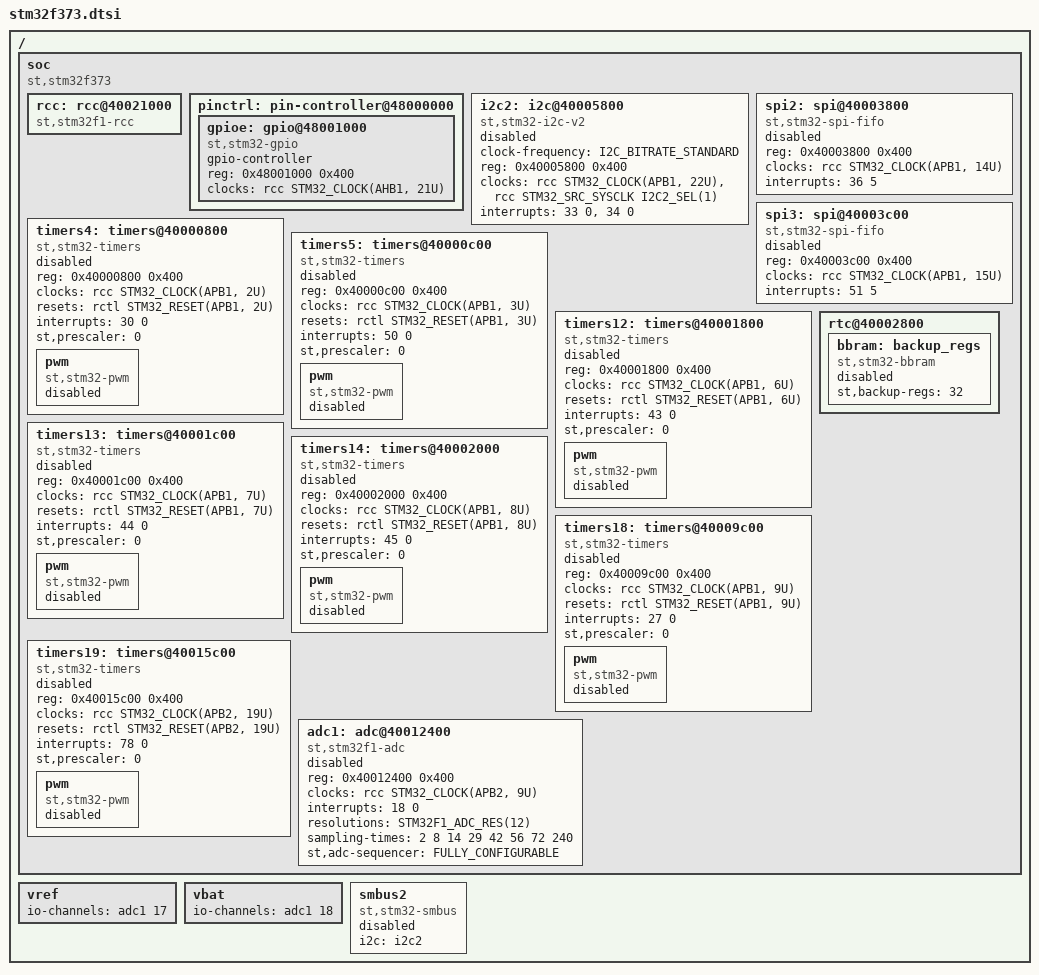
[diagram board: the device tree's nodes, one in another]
/*
 * Copyright (c) 2017 Linaro Limited
 *
 * SPDX-License-Identifier: Apache-2.0
 */

#include <st/f3/stm32f3.dtsi>
#include <zephyr/dt-bindings/adc/stm32f1_adc.h>

/ {
	soc {
		compatible = "st,stm32f373", "st,stm32f3", "simple-bus";

		rcc: rcc@40021000 {
			/*
			 * Use the STM32F1 compatible that define the same ADC
			 * prescaler in the RCC register
			 */
			compatible = "st,stm32f1-rcc";
		};

		pinctrl: pin-controller@48000000 {
			gpioe: gpio@48001000 {
				compatible = "st,stm32-gpio";
				gpio-controller;
				#gpio-cells = <2>;
				reg = <0x48001000 0x400>;
				clocks = <&rcc STM32_CLOCK(AHB1, 21U)>;
			};
		};

		i2c2: i2c@40005800 {
			compatible = "st,stm32-i2c-v2";
			clock-frequency = <I2C_BITRATE_STANDARD>;
			#address-cells = <1>;
			#size-cells = <0>;
			reg = <0x40005800 0x400>;
			clocks = <&rcc STM32_CLOCK(APB1, 22U)>,
				 /* I2C clock source should always be defined,
				  * even for the default value
				  */
				 <&rcc STM32_SRC_SYSCLK I2C2_SEL(1)>;
			interrupts = <33 0>, <34 0>;
			interrupt-names = "event", "error";
			status = "disabled";
		};

		spi2: spi@40003800 {
			compatible = "st,stm32-spi-fifo", "st,stm32-spi";
			#address-cells = <1>;
			#size-cells = <0>;
			reg = <0x40003800 0x400>;
			clocks = <&rcc STM32_CLOCK(APB1, 14U)>;
			interrupts = <36 5>;
			status = "disabled";
		};

		spi3: spi@40003c00 {
			compatible = "st,stm32-spi-fifo", "st,stm32-spi";
			#address-cells = <1>;
			#size-cells = <0>;
			reg = <0x40003c00 0x400>;
			clocks = <&rcc STM32_CLOCK(APB1, 15U)>;
			interrupts = <51 5>;
			status = "disabled";
		};

		timers4: timers@40000800 {
			compatible = "st,stm32-timers";
			reg = <0x40000800 0x400>;
			clocks = <&rcc STM32_CLOCK(APB1, 2U)>;
			resets = <&rctl STM32_RESET(APB1, 2U)>;
			interrupts = <30 0>;
			interrupt-names = "global";
			st,prescaler = <0>;
			status = "disabled";

			pwm {
				compatible = "st,stm32-pwm";
				status = "disabled";
				#pwm-cells = <3>;
			};
		};

		timers5: timers@40000c00 {
			compatible = "st,stm32-timers";
			reg = <0x40000c00 0x400>;
			clocks = <&rcc STM32_CLOCK(APB1, 3U)>;
			resets = <&rctl STM32_RESET(APB1, 3U)>;
			interrupts = <50 0>;
			interrupt-names = "global";
			st,prescaler = <0>;
			status = "disabled";

			pwm {
				compatible = "st,stm32-pwm";
				status = "disabled";
				#pwm-cells = <3>;
			};
		};

		timers12: timers@40001800 {
			compatible = "st,stm32-timers";
			reg = <0x40001800 0x400>;
			clocks = <&rcc STM32_CLOCK(APB1, 6U)>;
			resets = <&rctl STM32_RESET(APB1, 6U)>;
			interrupts = <43 0>;
			interrupt-names = "global";
			st,prescaler = <0>;
			status = "disabled";

			pwm {
				compatible = "st,stm32-pwm";
				status = "disabled";
				#pwm-cells = <3>;
			};
		};

		timers13: timers@40001c00 {
			compatible = "st,stm32-timers";
			reg = <0x40001c00 0x400>;
			clocks = <&rcc STM32_CLOCK(APB1, 7U)>;
			resets = <&rctl STM32_RESET(APB1, 7U)>;
			interrupts = <44 0>;
			interrupt-names = "global";
			st,prescaler = <0>;
			status = "disabled";

			pwm {
				compatible = "st,stm32-pwm";
				status = "disabled";
				#pwm-cells = <3>;
			};
		};

		timers14: timers@40002000 {
			compatible = "st,stm32-timers";
			reg = <0x40002000 0x400>;
			clocks = <&rcc STM32_CLOCK(APB1, 8U)>;
			resets = <&rctl STM32_RESET(APB1, 8U)>;
			interrupts = <45 0>;
			interrupt-names = "global";
			st,prescaler = <0>;
			status = "disabled";

			pwm {
				compatible = "st,stm32-pwm";
				status = "disabled";
				#pwm-cells = <3>;
			};
		};

		timers18: timers@40009c00 {
			compatible = "st,stm32-timers";
			reg = <0x40009c00 0x400>;
			clocks = <&rcc STM32_CLOCK(APB1, 9U)>;
			resets = <&rctl STM32_RESET(APB1, 9U)>;
			interrupts = <27 0>;
			interrupt-names = "global";
			st,prescaler = <0>;
			status = "disabled";

			pwm {
				compatible = "st,stm32-pwm";
				status = "disabled";
				#pwm-cells = <3>;
			};
		};

		timers19: timers@40015c00 {
			compatible = "st,stm32-timers";
			reg = <0x40015c00 0x400>;
			clocks = <&rcc STM32_CLOCK(APB2, 19U)>;
			resets = <&rctl STM32_RESET(APB2, 19U)>;
			interrupts = <78 0>;
			interrupt-names = "global";
			st,prescaler = <0>;
			status = "disabled";

			pwm {
				compatible = "st,stm32-pwm";
				status = "disabled";
				#pwm-cells = <3>;
			};
		};

		adc1: adc@40012400 {
			compatible = "st,stm32f1-adc", "st,stm32-adc";
			reg = <0x40012400 0x400>;
			clocks = <&rcc STM32_CLOCK(APB2, 9U)>;
			interrupts = <18 0>;
			status = "disabled";
			#io-channel-cells = <1>;
			resolutions = <STM32F1_ADC_RES(12)>;
			sampling-times = <2 8 14 29 42 56 72 240>;
			st,adc-sequencer = <FULLY_CONFIGURABLE>;
		};

		rtc@40002800 {
			bbram: backup_regs {
				compatible = "st,stm32-bbram";
				st,backup-regs = <32>;
				status = "disabled";
			};
		};
	};

	vref: vref {
		io-channels = <&adc1 17>;
	};

	vbat: vbat {
		io-channels = <&adc1 18>;
	};

	smbus2: smbus2 {
		compatible = "st,stm32-smbus";
		#address-cells = <1>;
		#size-cells = <0>;
		i2c = <&i2c2>;
		status = "disabled";
	};
};
